# cm4 register map
Registers are 32-bit, read-write, no defined reset value unless marked. A register's access mark holds for its fields unless they carry their own. Offsets are from the block's base; [hi:lo] are bit positions; lines under a group give offsets from that group; {n}, {i} and the like mark numbered series.

## SCB — System control block
Base 0xE000E000
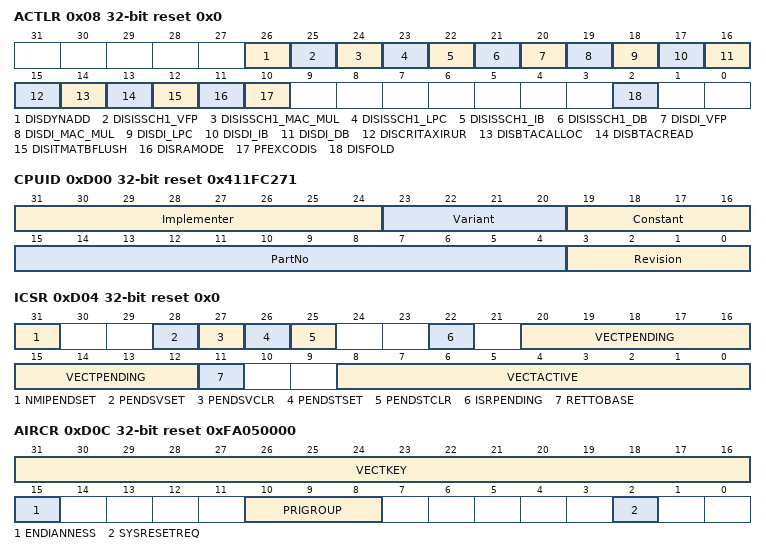
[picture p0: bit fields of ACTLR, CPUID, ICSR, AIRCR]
0x08 ACTLR access per field reset 0x0 — Auxiliary Control Register. The ACTLR provides disable bits for the following processor functions: FPU exception outputs, Dual-issue functionality, Flushing of the trace output from the ITM and DWT, Dynamic read allocate mode. By default this register is set to provide optimum performance from the Cortex-M7 processor, and does not normally require modification.
  [26] DISDYNADD rw — Disables dybnamic allocation of ADD ans SUB instructions:
    0=Normal operation. Some ADD and SUB instructions are resolved in EX1.; 1=Disable (All ADD and SUB instructions are resolved in EX2.)
  [25] DISISSCH1_VFP rw — Disables VFP instructions in channel 1:
    0=Normal operation; 1=Disable (VFP instruction type cannot be issued in channel 1)
  [24] DISISSCH1_MAC_MUL rw — Disables integer MAC and MUL instructions in channel 1:
    0=Normal operation; 1=Disable (Integer MAC and MUL instruction type cannot be issued in channel 1)
  [23] DISISSCH1_LPC rw — Disables loads to PC instructions in channel 1:
    0=Normal operation; 1=Disable (Loads to PC instruction type cannot be issued in channel 1)
  [22] DISISSCH1_IB rw — Disables indirect branches instructions in channel 1:
    0=Normal operation; 1=Disable (Indirect branches, but not loads to PC instruction type cannot be issued in channel 1)
  [21] DISISSCH1_DB rw — Disables direct branches instructions in channel 1:
    0=Normal operation; 1=Disable (Direct branches instruction type cannot be issued in channel 1)
  [20] DISDI_VFP rw — Disables VFP dual-issued instruction:
    0=Normal operation; 1=Disable (VFP instruction type cannot be dual-issued in channel 0)
  [19] DISDI_MAC_MUL rw — Disables integer MAC and MUL dual-issued instructions:
    0=Normal operation; 1=Disable (Integer MAC and MUL instruction type cannot be dual-issued in channel 0)
  [18] DISDI_LPC rw — Disables dual-issued loads to PC:
    0=Normal operation; 1=Disable (Loads to PC instruction type cannot be dual-issued in channel 0)
  [17] DISDI_IB rw — Disables dual-issued indirect branches:
    0=Normal operation; 1=Disable (Indirect branches, but not loads to PC instruction type cannot be dual-issued in channel 0)
  [16] DISDI_DB rw — Disables dual-issued direct branches:
    0=Normal operation; 1=Disable (Direct branches instruction type cannot be dual-issued in channel 0)
  [15] DISCRITAXIRUR rw — Disables critical AXI Read-Under-Read:
    0=Normal operation; 1=Disable (An AXI read to Strongly-ordered or device memory, or an LDREX to shared memory, is not put on AXI if there are any outstanding reads on AXI. Transactions on AXI cannot be interrupted. This bit might reduce the time that these transactions are in progress and might improve worst case interrupt latency. Performance is decreased when this bit is set.)
  [14] DISBTACALLOC rw — Disables the Branch Target Address Cache allocation:
    0=Normal operation; 1=Disable (No new entries are allocated in BTAC, but existing entries can be updated.)
  [13] DISBTACREAD rw — Disables the Branch Target Address Cache (BTAC):
    0=Normal operation; 1=Disable (BTAC is not used and only static branch prediction can occur.)
  [12] DISITMATBFLUSH ro — Disables ITM and DWT ATB flush:
    1=Disable (ITM and DWT ATB flush disabled. AFVALID is ignored and AFREADY is held HIGH.)
  [11] DISRAMODE rw — Disables dynamic read allocate mode for Write-Back Write-Allocate memory regions:
    0=Normal operation; 1=Disable (Dynamic disabled.)
  [10] PFEXCODIS rw — Disabled FPU exception outputs
    0=Normal operation; 1=Disable (FPU exception outputs are disabled.)
  [2] DISFOLD rw — Disables Interruption Folding
    0=Normal (Interruption folding enabled); 1=Disable (Interruption folding disabled)
0xD00 CPUID ro reset 0x411FC271 — CPUID Base Register
  [31:24] Implementer — Implementer code.
    65=ARM
  [23:20] Variant — Variant number, the r value in the rnpn product revision identifier.
    0=r0 (Revision 0); 1=r1 (Revision 1)
  [19:16] Constant — Reads as 0xF.
  [15:4] PartNo — Part number of the processor.
    0xC27=Cortex_M7 (Cortes-M7)
  [3:0] Revision — Revision number, the p value in the rnpn product revision identifier.
    0=p0 (Patch 0); 1=p1 (Patch 1); 2=p2 (Patch 2)
0xD04 ICSR access per field reset 0x0 — Interrupt Control and State Register
  [31] NMIPENDSET rw — NMI set-pending bit.
  [28] PENDSVSET rw — PendSV set-pending bit.
  [27] PENDSVCLR wo — PendSV clear-pending bit.
  [26] PENDSTSET rw — SysTick exception set-pending bit.
  [25] PENDSTCLR wo — SysTick exception clear-pending bit.
  [22] ISRPENDING rw — Interrupt pending flag, excluding NMI and Faults
  [20:12] VECTPENDING ro — Indicates the exception number of the highest priority pending enabled exception.
  [11] RETTOBASE ro — Indicates whether there are preempted active exceptions.
    0=Preempted (There are preempted active exceptions to execute.); 1=No_Preempted (There are no active exceptions, or the currently-executing exception is the only active exception.)
  [8:0] VECTACTIVE ro — Contains the active exception number. Subtract 16 from this value to obtain the CMSIS IRQ number required to index into the Interrupt Clear-Enable, Set-Enable, Clear-Pending, Set-Pending or Priority Registers.
0xD08 VTOR reset 0x0 — Vector Table Offset Register
  [31:0] TBLOFF — Vector table base offset field. It contains bits [29:7] of the offset of the table base from the bottom of the memory map. The lower bit in the TBLOFF field is implementation defined. When setting TBLOFF, you must align the offset of the number of exception entries in the vector table. The minimum alignment is 32 words, enough for up to 16 interupts. For more interrupts, adjust the alignment by rounding up to the next power of two. For example, if you require 21 interrupts, the alignment must be on a 64-word boundary because the required table size is 37 words, and the next power of two is 64.
0xD0C AIRCR access per field reset 0xFA050000 — Application Interrupt and Reset Control Register
  [31:16] VECTKEY rw — Register key. On write, write 0x5FA to VECTKEY, otherwise the write is ignored. Reads as 0xFA05
    0x5FA=Key (The write key); 0xFA05=Key_Read (The read key)
  [15] ENDIANNESS ro — Data endianness bit setting is implementation defined.
    0=Little_Endian (Data is little endian); 1=Big_Endian (Data is big endian)
  [10:8] PRIGROUP rw — Interrupt priority grouping field. This field determines the split of group priority from subpriority.
    0=Bxxxxxxx_y (Group priority bits: [7:1], subpriority bits [0]); 1=Bxxxxxx_yy (Group priority bits: [7:2], subpriority bits [1:0]); 2=Bxxxxx_yyy (Group priority bits: [7:3], subpriority bits [2:0]); 3=Bxxxx_yyyy (Group priority bits: [7:4], subpriority bits [3:0]); 4=Bxxx_yyyyy (Group priority bits: [7:5], subpriority bits [4:0]); 5=Bxx_yyyyyy (Group priority bits: [7:6], subpriority bits [5:0]); 6=Bx_yyyyyyy (Group priority bits: [7], subpriority bits [6:0]); 7=B_yyyyyyyy (Group priority bits: None, subpriority bits [7:0])
  [2] SYSRESETREQ wo — System reset request bit setting is implementation defined.
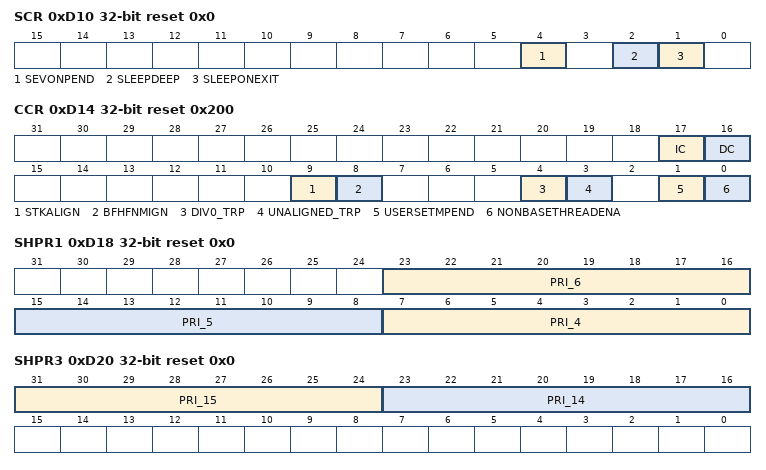
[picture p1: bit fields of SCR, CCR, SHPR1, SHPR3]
0xD10 SCR reset 0x0 — System Control Register
  [4] SEVONPEND — Send event on pending bit
  [2] SLEEPDEEP — Controls whether the processor uses sleep or deep sleep as its low-power mode
  [1] SLEEPONEXIT — Indicates sleep-on-exit when returning from Handler mode to Thread mode
0xD14 CCR access per field reset 0x200 — Configuration and Control Register
  [17] IC rw — Enables L1 instruction cache.
  [16] DC rw — Enables L1 data cache.
  [9] STKALIGN ro — Always reads-as-one. It indicates stack alignment on exception entry is 8-byte aligned.
  [8] BFHFNMIGN rw — Enables handlers with priority -1 or -2 to ignore data BusFaults caused by load and store instructions. This applies to the hard fault, NMI, and FAULTMASK escalated handlers.
  [4] DIV0_TRP rw — Enables faulting or halting when the processor executes an SDIF or UDIV instruction with a divisor of 0.
  [3] UNALIGNED_TRP rw — Enables unalign access traps.
  [1] USERSETMPEND rw — Enables unprivileged software access to the STIR
  [0] NONBASETHREADENA rw — Indicates how the processor enters Thread mode
    0=No_Active_Exception (Processor can enter Thread mode only when no exception is active); 1=On_Exc_Return (Processor can enter Thread mode from any level under the control of an EXC_RETURN value)
0xD18 SHPR1 reset 0x0 — System Handler Priority Register 1
  [23:16] PRI_6 — Priority of the system handler, UsageFault
  [15:8] PRI_5 — Priority of the system handler, BusFault
  [7:0] PRI_4 — Priority of the system handler, MemManage
0xD1C SHPR2 reset 0x0 — System Handler Priority Register 2
  [31:24] PRI_11 — Priority of the system handler, SVCall
0xD20 SHPR3 reset 0x0 — System Handler Priority Register 3
  [31:24] PRI_15 — Priority of the system handler, SysTick
  [23:16] PRI_14 — Priority of the system handler, PendSV
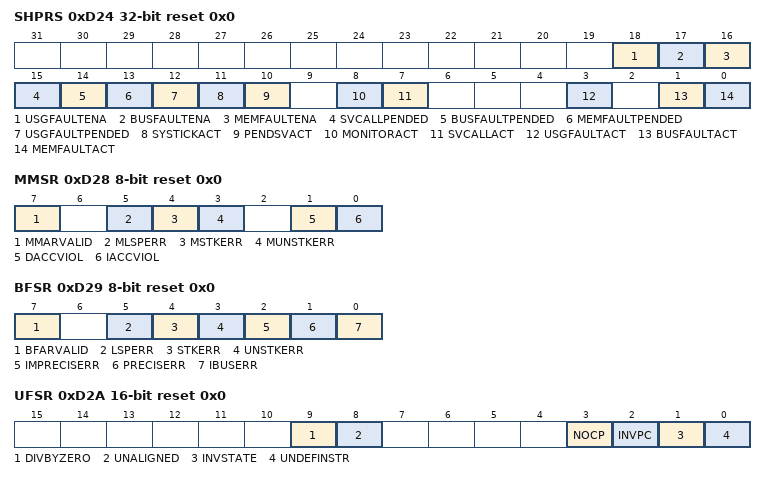
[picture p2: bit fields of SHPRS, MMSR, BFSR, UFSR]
0xD24 SHPRS access per field reset 0x0 — System Handler Control and State Register
  [18] USGFAULTENA rw — UsageFault enable bit, set to 1 to enable
  [17] BUSFAULTENA rw — BusFault enable bit, set to 1 to enable
  [16] MEMFAULTENA rw — MemManage enable bit, set to 1 to enable
  [15] SVCALLPENDED ro — SVCall pending bit, reads as 1 if exception is pending
  [14] BUSFAULTPENDED ro — BusFault exception pending bit, reads as 1 if exception is pending
  [13] MEMFAULTPENDED ro — MemManage exception pending bit, reads as 1 if exception is pending
  [12] USGFAULTPENDED ro — UsageFault exception pending bit, reads as 1 if exception is pending
  [11] SYSTICKACT ro — Systick exception active bit, reads as 1 if exception is active.
  [10] PENDSVACT ro — PendSV exception active bit, reads as 1 if exception is active.
  [8] MONITORACT ro — Debug Monitor active bit, reads as 1 if exception is active.
  [7] SVCALLACT ro — SVCall active bit, reads as 1 if exception is active.
  [3] USGFAULTACT ro — UsageFault exception active bit, reads as 1 if exception is active.
  [1] BUSFAULTACT ro — BusFault exception active bit, reads as 1 if exception is active.
  [0] MEMFAULTACT ro — MemManage exception active bit, reads as 1 if exception is active.
0xD28 MMSR 8-bit reset 0x0 — MemManage Fault Status Register
  [7] MMARVALID — MemManage fault address register valid flag.
  [5] MLSPERR — MemManage fault during floating-point lazy state preservation.
  [4] MSTKERR — MemManage fault on stacking for exception entry
  [3] MUNSTKERR — MemManage fault on unstacking for a return from exception
  [1] DACCVIOL — Data access violation flag
  [0] IACCVIOL — Instruction access violation flag
0xD29 BFSR 8-bit reset 0x0 — BusFault Status Register
  [7] BFARVALID — BusFault Address Register valid flag.
  [5] LSPERR — BusFault on floating-point lazy state preservation.
  [4] STKERR — BusFault on stacking for exception entry.
  [3] UNSTKERR — BusFault on unstacking for a return from exception.
  [2] IMPRECISERR — Precise data bus error
  [1] PRECISERR — Precise data bus error
  [0] IBUSERR — Instruction bus error
0xD2A UFSR 16-bit reset 0x0 — UsageFault Status Register
  [9] DIVBYZERO — Divide by zero UsageFault.
  [8] UNALIGNED — Unaligned access UsageFault
  [3] NOCP — No coprocessor UsageFault
  [2] INVPC — Invalid PC load UsageFault, caused by an invalid PC load by EXC_RETURN
  [1] INVSTATE — Invalid State UsageFault
  [0] UNDEFINSTR — Undefined instruction UsageFault
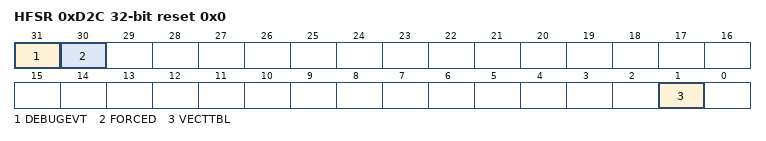
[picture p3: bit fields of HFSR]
0xD2C HFSR reset 0x0 — HardFault Status Register
  [31] DEBUGEVT — Reserved for Debug use. When writing to the register, you must write 1 to this bit, otherwise behavior is UNPREDICTABLE.
  [30] FORCED — Indicates a forced hard fault, generated by escalation of a fault with configurable priority that cannot be handled, either because of priority or because it is disabled.
  [1] VECTTBL — Indicates a BusFault on a vector table read during exception processing.
0xD34 MMAR reset 0x0 — MemManage Fault Address Register
  [31:0] ADDRESS
0xD38 BFAR reset 0x0 — BusFault Address Register
  [31:0] ADDRESS

## Debug
Base 0xE000ED00
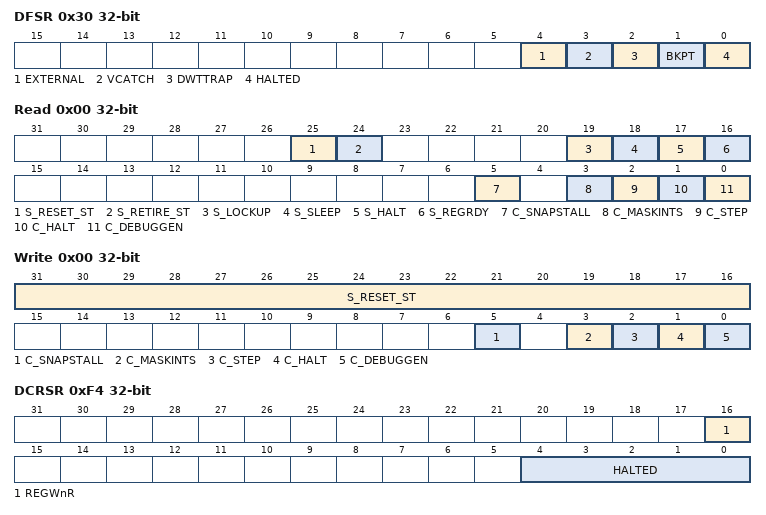
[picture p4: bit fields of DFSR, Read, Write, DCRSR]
0x30 DFSR — Debug Fault Status Register
  [4] EXTERNAL — An asynchronous exception generated due to the assertion of EDBGRQ.
  [3] VCATCH — Vector catch triggered. Corresponding FSR will contain the primary cause of the exception.
  [2] DWTTRAP — Data Watchpoint and Trace trap. Indicates that the core halted due to at least one DWT trap event.
  [1] BKPT — BKPT instruction executed or breakpoint match in FPB.
  [0] HALTED
0xF0 DHCSR group — Debug Halting Control and Status Register
  0x00 Read ro
    [25] S_RESET_ST, [24] S_RETIRE_ST, [19] S_LOCKUP, [18] S_SLEEP, [17] S_HALT, [16] S_REGRDY, [5] C_SNAPSTALL, [3] C_MASKINTS, [2] C_STEP, [1] C_HALT, [0] C_DEBUGGEN
  0x00 Write wo (alternate view of DHCSR_Read)
    [31:16] S_RESET_ST — Debug Key. The value 0xA05F must be written to enable write accesses to bits [15:0], otherwise the write access will be ignored. Read behavior of bits [31:16] is as listed below.
    [5] C_SNAPSTALL
    [3] C_MASKINTS
    [2] C_STEP
    [1] C_HALT
    [0] C_DEBUGGEN
0xF4 DCRSR wo — Debug Core Register Selector Register: The DCRSR write-only register generates a handshake to the core to transfer the selected register to/from the DCRDR. The DHCSR S_REGRDY bit is cleared when the DCRSR is written, and remains clear until the core transaction completes. This register is only accessible from Debug state.
  [16] REGWnR
    1=Write; 0=Read
  [4:0] HALTED
    {v}=Register_{v} (v=0..12); 13=Current_SP; 14=Link_Rregister; 15=Debug_Return_Address; 16=xPSR; 17=MSP; 18=PSP; 19=CONTROL_FAULTMASK_BASEPRI_PRIMASK
0xF8 DCRDR — Debug Core Register Data Register
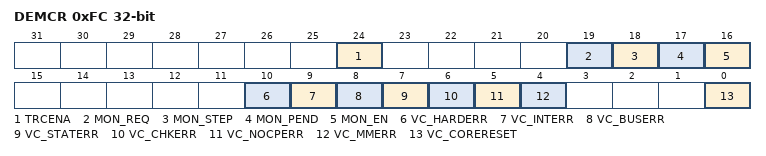
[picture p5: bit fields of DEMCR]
0xFC DEMCR — Debug Exception and Monitor Control Register
  [24] TRCENA, [19] MON_REQ, [18] MON_STEP, [17] MON_PEND, [16] MON_EN, [10] VC_HARDERR, [9] VC_INTERR, [8] VC_BUSERR, [7] VC_STATERR, [6] VC_CHKERR, [5] VC_NOCPERR, [4] VC_MMERR, [0] VC_CORERESET

## DWT — Data Watchpoint Trace
Base 0xE0001000
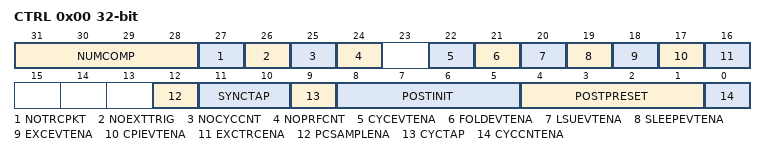
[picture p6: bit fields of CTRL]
0x00 CTRL — Control Register
  [31:28] NUMCOMP — Number of comparators
  [27] NOTRCPKT — No trace sampling and exception tracing
  [26] NOEXTTRIG — No external match signals
  [25] NOCYCCNT — No cycle counter
  [24] NOPRFCNT — No profiling counters
  [22] CYCEVTENA — enable Cycle count event
  [21] FOLDEVTENA — enable Folded instruction count event
  [20] LSUEVTENA — enable Load Store Unit (LSU) count event
  [19] SLEEPEVTENA — enable Sleep count event
  [18] EXCEVTENA — enable interrupt overhead event
  [17] CPIEVTENA — enable CPI count event
  [16] EXCTRCENA — enable interrupt event tracing
  [12] PCSAMPLENA — enable POSTCNT as timer for PC sample packets
  [11:10] SYNCTAP — ???
  [9] CYCTAP — ???
  [8:5] POSTINIT — ???
  [4:1] POSTPRESET — ???
  [0] CYCCNTENA — enable cycle counter
0x04 CYCCNT — Cycle Count Register
0x08 CPICNT — CPI Count Register
0x0C EXCCNT — Exception Overhead Count Register
0x10 SLEEPCNT — Sleep Count Register
0x14 LSUCNT — LSU Count Register
0x18 FOLDCNT — Folded-instruction Count Register
0x1C PCSR — Program Counter Sample Register
{0x20+0x10*i} COMP{i} (i=0..3) — Comparator Register {i}
{0x24+0x10*i} MASK{i} (i=0..3) — Mask Register {i}
{0x28+0x10*i} FUNCTION{i} (i=0..3) — Function Register {i}
